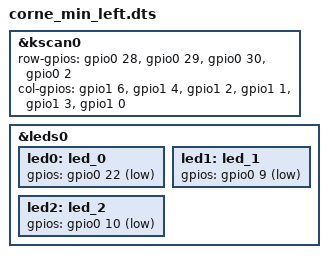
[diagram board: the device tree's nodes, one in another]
#include "corne_min.dtsi"

&kscan0 {
    row-gpios
        = <&gpio0 28 (GPIO_ACTIVE_HIGH | GPIO_PULL_DOWN)>
        , <&gpio0 29 (GPIO_ACTIVE_HIGH | GPIO_PULL_DOWN)>
        , <&gpio0 30 (GPIO_ACTIVE_HIGH | GPIO_PULL_DOWN)>
        , <&gpio0  2 (GPIO_ACTIVE_HIGH | GPIO_PULL_DOWN)>
        ;

    col-gpios
        = <&gpio1  6 GPIO_ACTIVE_HIGH>
        , <&gpio1  4 GPIO_ACTIVE_HIGH>
        , <&gpio1  2 GPIO_ACTIVE_HIGH>
        , <&gpio1  1 GPIO_ACTIVE_HIGH>
        , <&gpio1  3 GPIO_ACTIVE_HIGH>
        , <&gpio1  0 GPIO_ACTIVE_HIGH>
        ;
};

&leds0 {
    led0: led_0 {
        gpios = <&gpio0 22 GPIO_ACTIVE_LOW>;  // red LED
    };
    led1: led_1 {
        gpios = <&gpio0 9 GPIO_ACTIVE_LOW>;  // green LED
    };
    led2: led_2 {
        gpios = <&gpio0 10 GPIO_ACTIVE_LOW>;  // blue LED
    };
};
